AUTOSAR XML (schema 4-3-0)
standard types defined: uint8
package /DataTypes
  app type App_uint8: category=VALUE, sw-calibration-access=READ-ONLY, compu {identical}, range raw 0..255
  app type App_WindowPosition: category=VALUE, sw-calibration-access=READ-ONLY, compu {identical}, range raw 0..100
  app type App_RequestedDirection: category=VALUE, sw-calibration-access=READ-ONLY, compu {identical}, range raw 0..3
package /DataTypes/Units
  unit No_Unit: display-name=-, factor-si-to-unit=1, offset-si-to-unit=0
package /ComponentTypes
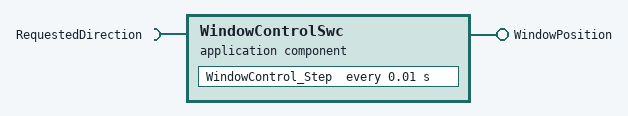
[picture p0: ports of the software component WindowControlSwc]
  application sw component type WindowControlSwc
    require port RequestedDirection: nonqueued-receiver-com-spec{data-element=RequestedDirection, filter=data-filter-type=ALWAYS, init-value=0}, required-interface=RequestedDirection
    provide port WindowPosition: nonqueued-sender-com-spec{data-element=WindowPosition, init-value=0}, provided-interface=WindowPosition
    behavior WindowControlSwc_InternalBehavior: data-type-mapping=DataMapping
      timing event TMT_WindowControl_Step: start-on-event=WindowControl_Step, period=0.01
      runnable WindowControl_Step
        data-receive-point-by-arguments:
          access DataRead_RequestedDirection_RequestedDirection: accessed-variable=RequestedDirection.RequestedDirection
        data-send-points:
          access DataWrite_WindowPosition_WindowPosition: accessed-variable=WindowPosition.WindowPosition
package /ComponentTypes/MappingSets
  data type mapping set DataMapping
    data-type-maps:
      application-data-type=App_uint8, implementation-data-type=uint8
      application-data-type=App_WindowPosition, implementation-data-type=uint8
      application-data-type=App_RequestedDirection, implementation-data-type=uint8
package /PortInterfaces
  sender receiver interface WindowPosition
    data WindowPosition: type=App_WindowPosition
  sender receiver interface RequestedDirection
    data RequestedDirection: type=App_RequestedDirection
